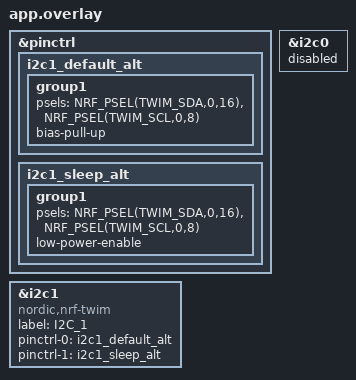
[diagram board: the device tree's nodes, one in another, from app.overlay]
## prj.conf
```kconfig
CONFIG_STDOUT_CONSOLE=y
CONFIG_GPIO=y
CONFIG_I2C=y
#need to turn these off for microbit v2 as they prevent low level fiddling with the i2c devices
CONFIG_LIS2DH=n
CONFIG_LIS2MDL=n
```

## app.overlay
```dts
/*
 *
 * SPDX-License-Identifier: Apache-2.0
 */

&pinctrl {
    /* IMPORTANT!  There should not be a space before the : in the next line (and similar below) */


    i2c1_default_alt: i2c1_default_alt {
        group1 {
            psels = <NRF_PSEL(TWIM_SDA,0,16)>,
                    <NRF_PSEL(TWIM_SCL,0,8)>;
            bias-pull-up;
        };
    };
    i2c1_sleep_alt: i2c1_sleep_alt {
        group1 {
            psels = <NRF_PSEL(TWIM_SDA,0,16)>,
                    <NRF_PSEL(TWIM_SCL,0,8)>;
            low-power-enable;
        };
    };

    
    
};
&i2c0 {

    status = "disabled";
};

&i2c1 {
	compatible = "nordic,nrf-twim";
	status = "okay";
	label="I2C_1"; 
    pinctrl-0 = <&i2c1_default_alt>;
    pinctrl-1 = <&i2c1_sleep_alt>;
    pinctrl-names = "default", "sleep";
};
```

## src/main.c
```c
/*
 * SPDX-License-Identifier: Apache-2.0
*/

#include <zephyr/zephyr.h>
#include <zephyr/sys/printk.h>
#include <zephyr/device.h>	
#include <stdio.h>
#include <string.h>
#include "lsm303_ll.h"

void main(void)
{
	int ret;
		
	ret = lsm303_ll_begin();
	if (ret < 0)
	{
		printf("\nError initializing lsm303.  Error code = %d\n",ret);	
		while(1);
	}
	while(1)
	{    
        printf("Accel Y (x100) = %d\n",lsm303_ll_readAccelY());
         k_msleep(100);

	}
}
```

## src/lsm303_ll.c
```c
#include <zephyr/sys/printk.h>
#include <zephyr/device.h>
#include <zephyr/drivers/gpio.h>
#include <zephyr/drivers/spi.h>
#include <zephyr/drivers/i2c.h>
#include <stdio.h>
#include <stdint.h>
#include "lsm303_ll.h"

int lsm303_ll_readRegister(uint8_t RegNum, uint8_t *Value);
int lsm303_ll_writeRegister(uint8_t RegNum, uint8_t Value);
void readCalibrationData();
//static const struct spi_config * cfg;
static const struct device *i2c;
int lsm303_ll_begin()
{
	int nack;
	uint8_t device_id;
	// Set up the I2C interface
	i2c = device_get_binding("I2C_1");
	if (i2c==NULL)
	{
		printf("Error acquiring i2c1 interface\n");
		return -1;
	}	
	// Check to make sure the device is present by reading the WHO_AM_I register
	
    nack = lsm303_ll_readRegister(0x0f,&device_id);
    if (nack != 0)
	{
		printf("Error finding LSM303 on the I2C bus\n");
		return -2;
	}
	else	
	{
		printf("Found LSM303.  WHO_AM_I = %d\n",device_id);
	}
	lsm303_ll_writeRegister(0x20,0x77); //wake up LSM303 (max speed, all accel channels)i2c_reg_read_byte
	lsm303_ll_writeRegister(0x23,0x08); //enable  high resolution mode +/- 2g
	
	return 0;
}

int lsm303_ll_readAccelY() // returns Temperature * 100
{
	int16_t accel;
	uint8_t buf[2];
	buf[0] = 0x80+0x2a;	
	i2c_burst_read(i2c,LSM303_ACCEL_ADDRESS,0xaa, buf,2);
	accel = buf[1];
	accel = accel << 8;
	accel = accel + buf[0];
	accel = accel / 16; // must shift right 4 bits as this is a left justified 12 bit result
	// now scale to m^3/s * 100.
	// +2047 = +2g
	int accel_32bit = accel; // go to be wary of numeric overflow
	accel_32bit = accel_32bit * 2*981 / 2047;
    return accel_32bit;    
}

int lsm303_ll_readRegister(uint8_t RegNum, uint8_t *Value)
{
	    //reads a byte from a specific register
    int nack;   
	nack=i2c_reg_read_byte(i2c,LSM303_ACCEL_ADDRESS,RegNum,Value);
	return nack;
}
int lsm303_ll_writeRegister(uint8_t RegNum, uint8_t Value)
{
	//writes a byte to a specific register
    uint8_t Buffer[2];    
    Buffer[0]= Value;    
    int nack;    
	nack=i2c_reg_write_byte(i2c,LSM303_ACCEL_ADDRESS,RegNum,Value);
    return nack;
}
```
